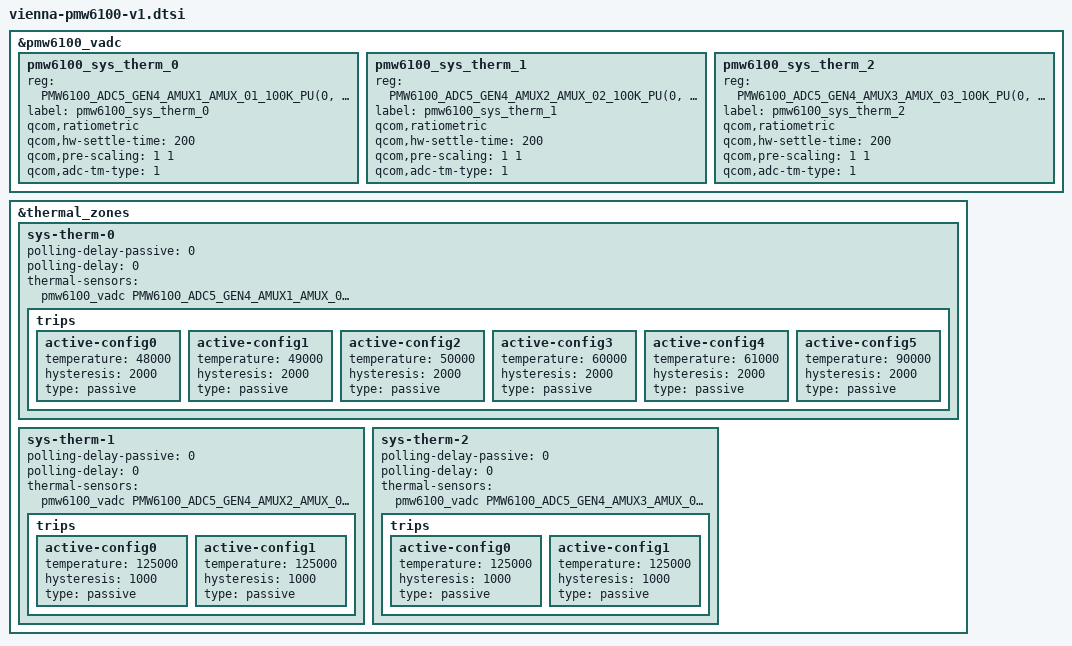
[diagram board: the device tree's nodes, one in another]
// SPDX-License-Identifier: BSD-3-Clause
/*
 * Copyright (c) Qualcomm Technologies, Inc. and/or its subsidiaries.
 */

#include <dt-bindings/iio/qcom,spmi-adc5-gen4-pmw6100.h>

&pmw6100_vadc {
	pmw6100_sys_therm_0 {
		reg = <PMW6100_ADC5_GEN4_AMUX1_AMUX_01_100K_PU(0, PMW6100_SID)>;
		label = "pmw6100_sys_therm_0";
		qcom,ratiometric;
		qcom,hw-settle-time = <200>;
		qcom,pre-scaling = <1 1>;
		qcom,adc-tm-type = <1>;
	};

	pmw6100_sys_therm_1 {
		reg = <PMW6100_ADC5_GEN4_AMUX2_AMUX_02_100K_PU(0, PMW6100_SID)>;
		label = "pmw6100_sys_therm_1";
		qcom,ratiometric;
		qcom,hw-settle-time = <200>;
		qcom,pre-scaling = <1 1>;
		qcom,adc-tm-type = <1>;
	};

	pmw6100_sys_therm_2 {
		reg = <PMW6100_ADC5_GEN4_AMUX3_AMUX_03_100K_PU(0, PMW6100_SID)>;
		label = "pmw6100_sys_therm_2";
		qcom,ratiometric;
		qcom,hw-settle-time = <200>;
		qcom,pre-scaling = <1 1>;
		qcom,adc-tm-type = <1>;
	};

};

&thermal_zones {
	sys-therm-0 {
		polling-delay-passive = <0>;
		polling-delay = <0>;
		thermal-sensors = <&pmw6100_vadc
				   PMW6100_ADC5_GEN4_AMUX1_AMUX_01_100K_PU(0, PMW6100_SID)>;

		trips {
			active-config0 {
				temperature = <48000>;
				hysteresis = <2000>;
				type = "passive";
			};

			active-config1 {
				temperature = <49000>;
				hysteresis = <2000>;
				type = "passive";
			};

			active-config2 {
				temperature = <50000>;
				hysteresis = <2000>;
				type = "passive";
			};

			active-config3 {
				temperature = <60000>;
				hysteresis = <2000>;
				type = "passive";
			};

			active-config4 {
				temperature = <61000>;
				hysteresis = <2000>;
				type = "passive";
			};

			active-config5 {
				temperature = <90000>;
				hysteresis = <2000>;
				type = "passive";
			};
		};
	};

	sys-therm-1 {
		polling-delay-passive = <0>;
		polling-delay = <0>;
		thermal-sensors = <&pmw6100_vadc
				   PMW6100_ADC5_GEN4_AMUX2_AMUX_02_100K_PU(0, PMW6100_SID)>;

		trips {
			active-config0 {
				temperature = <125000>;
				hysteresis = <1000>;
				type = "passive";
			};

			active-config1 {
				temperature = <125000>;
				hysteresis = <1000>;
				type = "passive";
			};
		};
	};

	sys-therm-2 {
		polling-delay-passive = <0>;
		polling-delay = <0>;
		thermal-sensors = <&pmw6100_vadc
				   PMW6100_ADC5_GEN4_AMUX3_AMUX_03_100K_PU(0, PMW6100_SID)>;

		trips {
			active-config0 {
				temperature = <125000>;
				hysteresis = <1000>;
				type = "passive";
			};

			active-config1 {
				temperature = <125000>;
				hysteresis = <1000>;
				type = "passive";
			};
		};
	};
};


